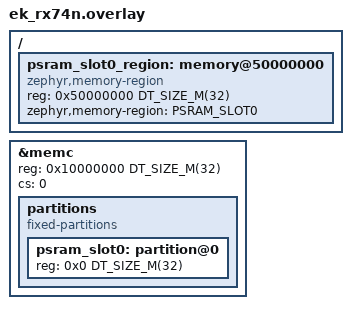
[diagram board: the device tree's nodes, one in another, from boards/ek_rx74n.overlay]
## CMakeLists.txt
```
# SPDX-License-Identifier: Apache-2.0

cmake_minimum_required(VERSION 3.20.0)

find_package(Zephyr REQUIRED HINTS $ENV{ZEPHYR_BASE})
project(code_relocation_nocopy)

FILE(GLOB app_sources src/*.c)
target_sources(app PRIVATE ${app_sources})

# Run ext_code from PSRAM (copied from flash at startup) on RX, or XIP on others.
if (CONFIG_BOOTLOADER_MCUBOOT)
zephyr_code_relocate(FILES src/ext_code.c LOCATION PSRAM_SLOT0_TEXT)
endif()

# But still relocate (copy) the data to RAM
zephyr_code_relocate(FILES src/ext_code.c LOCATION RAM_DATA)

# sram_code instead runs entirely from SRAM after being copied there.
zephyr_code_relocate(FILES src/sram_code.c LOCATION RAM)

# Relocate the RX context switch code to SRAM
zephyr_code_relocate(FILES ${ZEPHYR_BASE}/arch/rx/core/switch.S LOCATION RAM)

# Relocate the FSP group IRQ code to SRAM. NOKEEP drops the unused
# group_dmac_irq_isr, which references a callback list this sample does not define.
zephyr_code_relocate(FILES ${ZEPHYR_HAL_RENESAS_MODULE_DIR}/drivers/rx/fsp/src/bsp/mcu/all/bsp_group_irq.c
  LOCATION RAM NOKEEP)
```

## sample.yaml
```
sample:
  description: Code data relocation nocopy Sample
  name: code relocation nocopy
tests:
  sample.app_dev.renesas_code_relocation_nocopy:
    platform_allow:
      - ek_rx74m
    integration_platforms:
      - ek_rx74m
    tags: linker
    harness: console
    harness_config:
      type: one_line
      regex:
        - "Hello World! (.*)"
```

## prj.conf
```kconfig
CONFIG_CODE_DATA_RELOCATION=y
CONFIG_HAVE_CUSTOM_LINKER_SCRIPT=y
CONFIG_CUSTOM_LINKER_SCRIPT="linker_rx.ld"
CONFIG_COVERAGE=n
CONFIG_XIP=y
CONFIG_LOG=y
```

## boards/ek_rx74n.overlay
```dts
/delete-node/ &psram;

/ {
	psram_slot0_region: memory@50000000 {
		compatible = "zephyr,memory-region";
		reg = <0x50000000 DT_SIZE_M(32)>;
		zephyr,memory-region = "PSRAM_SLOT0";
	};
};

&memc {
	reg = <0x10000000 DT_SIZE_M(32)>;
	cs = <0>;
	status = "okay";
	partitions {
		compatible = "fixed-partitions";
		#address-cells = <1>;
		#size-cells = <1>;

		psram_slot0: partition@0 {
			reg = <0x0 DT_SIZE_M(32)>;
		};
	};
};
```

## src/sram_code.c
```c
/*
 * Copyright (c) 2022 Carlo Caione <ccaione@baylibre.com>
 *
 * SPDX-License-Identifier: Apache-2.0
 */

#include <zephyr/kernel.h>
#include <zephyr/sys/printk.h>

uint32_t var_sram_data = 10U;

/* Only the addresses are printed, to show where the relocated code ended up */
extern void switch_isr_wrapper(void);
extern void z_rx_arch_switch(void);
extern void group_irq_isr(void);
extern void bsp_group_irq_get_table_index(void);

void function_in_sram(void)
{
	printk("Address of %s %p\n", __func__, &function_in_sram);
	printk("Address of var_sram_data %p (%d)\n", &var_sram_data, var_sram_data);
	printk("Address of switch_isr_wrapper %p\n", &switch_isr_wrapper);
	printk("Address of z_rx_arch_switch %p\n", &z_rx_arch_switch);
	printk("Address of group_irq_isr %p\n", &group_irq_isr);
	printk("Address of bsp_group_irq_get_table_index %p\n", &bsp_group_irq_get_table_index);
}
```
